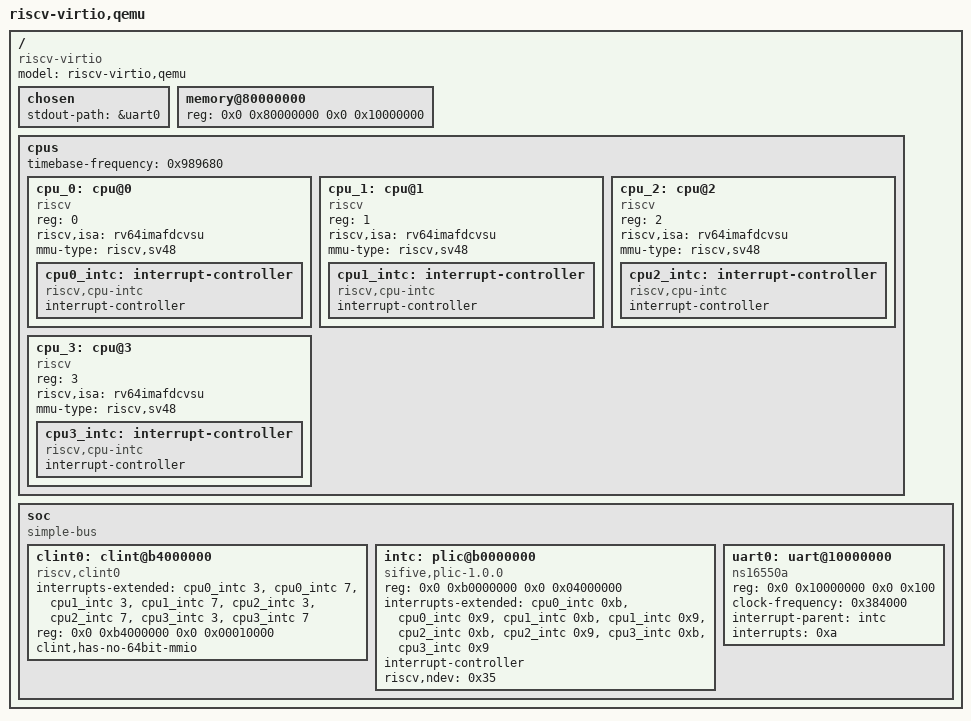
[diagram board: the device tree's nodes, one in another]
/dts-v1/;

/ {
	compatible = "riscv-virtio";
	model = "riscv-virtio,qemu";
	#address-cells = <0x2>;
	#size-cells = <0x2>;

	chosen {
		stdout-path = &uart0;
	};

	memory@80000000 {
		device_type = "memory";
		reg = <0x0 0x80000000 0x0 0x10000000>;
	};

	cpus {
		#address-cells = <0x1>;
		#size-cells = <0x0>;
		timebase-frequency = <0x989680>;

		cpu_0: cpu@0 {
			device_type = "cpu";
			reg = <0>;
			status = "okay";
			compatible = "riscv";
			riscv,isa = "rv64imafdcvsu";
			mmu-type = "riscv,sv48";

			cpu0_intc: interrupt-controller {
				#interrupt-cells = <1>;
				compatible = "riscv,cpu-intc";
				interrupt-controller;
			};
		};
		cpu_1: cpu@1 {
			device_type = "cpu";
			reg = <1>;
			status = "okay";
			compatible = "riscv";
			riscv,isa = "rv64imafdcvsu";
			mmu-type = "riscv,sv48";

			cpu1_intc: interrupt-controller {
				#interrupt-cells = <1>;
				compatible = "riscv,cpu-intc";
				interrupt-controller;
			};
		};
		cpu_2: cpu@2 {
			device_type = "cpu";
			reg = <2>;
			status = "okay";
			compatible = "riscv";
			riscv,isa = "rv64imafdcvsu";
			mmu-type = "riscv,sv48";

			cpu2_intc: interrupt-controller {
				#interrupt-cells = <1>;
				compatible = "riscv,cpu-intc";
				interrupt-controller;
			};
		};
		cpu_3: cpu@3 {
			device_type = "cpu";
			reg = <3>;
			status = "okay";
			compatible = "riscv";
			riscv,isa = "rv64imafdcvsu";
			mmu-type = "riscv,sv48";

			cpu3_intc: interrupt-controller {
				#interrupt-cells = <1>;
				compatible = "riscv,cpu-intc";
				interrupt-controller;
			};
		};
	};

	soc {
		compatible = "simple-bus";
		#address-cells = <2>;
		#size-cells = <2>;
		ranges;

		clint0: clint@b4000000 {
			compatible = "riscv,clint0";
			interrupts-extended = <
				&cpu0_intc  3 &cpu0_intc  7
				&cpu1_intc  3 &cpu1_intc  7
				&cpu2_intc  3 &cpu2_intc  7
				&cpu3_intc  3 &cpu3_intc  7
			>;
			reg = <0x0 0xb4000000 0x0 0x00010000>;
			clint,has-no-64bit-mmio;
		};

		intc:plic@b0000000 {
			compatible = "sifive,plic-1.0.0", "riscv,plic0";
			reg = <0x0 0xb0000000 0x0 0x04000000>;

			interrupts-extended = <
			    &cpu0_intc 0xb &cpu0_intc 0x9
			    &cpu1_intc 0xb &cpu1_intc 0x9
			    &cpu2_intc 0xb &cpu2_intc 0x9
			    &cpu3_intc 0xb &cpu3_intc 0x9
			>;
			interrupt-controller;
			#interrupt-cells = <0x1>;
			#address-cells = <0x0>;
			riscv,ndev = <0x35>;
		};

		uart0:uart@10000000 {
			compatible = "ns16550a";
			reg = <0x0 0x10000000 0x0 0x100>;
			clock-frequency = <0x384000>;

			interrupt-parent = <&intc>;
			interrupts = <0xa>;
		};
	};
};

